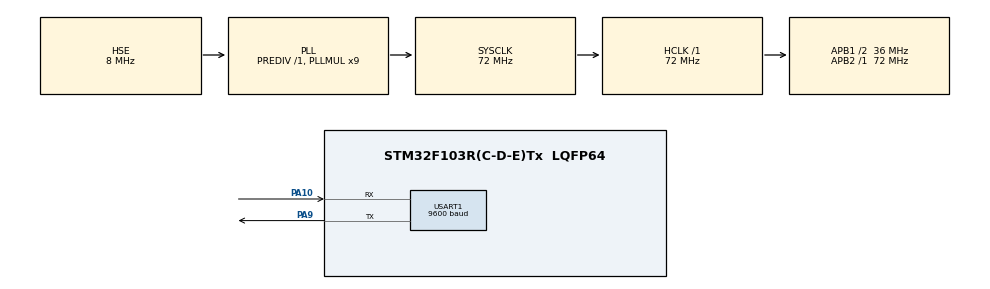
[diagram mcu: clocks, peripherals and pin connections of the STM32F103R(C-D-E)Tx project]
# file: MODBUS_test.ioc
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Mcu.Family=STM32F1
RCC.PLLSourceVirtual=RCC_PLLSOURCE_HSE
PD1-OSC_OUT.Mode=HSE-External-Oscillator
PA10.Mode=Asynchronous
USART1.BaudRate=9600
PD0-OSC_IN.Signal=RCC_OSC_IN
VP_RealThread.RT-Thread_VS_RTOSJjRTAaThread_3.1.3.Mode=RTOSJjRTAaThread
RCC.APB1CLKDivider=RCC_HCLK_DIV2
RCC.SYSCLKSource=RCC_SYSCLKSOURCE_PLLCLK
ProjectManager.StackSize=0x400
PD1-OSC_OUT.Signal=RCC_OSC_OUT
PA13.Signal=SYS_JTMS-SWDIO
PA9.Mode=Asynchronous
ProjectManager.TargetToolchain=Other Toolchains (GPDSC)
RCC.HCLKFreq_Value=72000000
RCC.APB2TimFreq_Value=72000000
PA9.Signal=USART1_TX
RCC.USBFreq_Value=72000000
RCC.AHBFreq_Value=72000000
PD0-OSC_IN.Mode=HSE-External-Oscillator
PB3.Mode=JTAG_4_pins
board=custom
PA15.Mode=JTAG_4_pins
RCC.PLLMUL=RCC_PLL_MUL9
RCC.APB2Freq_Value=72000000
PA14.Mode=JTAG_4_pins
PA13.Mode=JTAG_4_pins
Mcu.Name=STM32F103R(C-D-E)Tx
RealThread.RT-Thread.3.1.3.RTAaThreadCcRTOSJjkernel=true
RCC.LockedElements=AHBOutput
PB3.Signal=SYS_JTDO-TRACESWO
RCC.SYSCLKFreq_VALUE=72000000
Mcu.Package=LQFP64
USART1.VirtualMode=VM_ASYNC
PA10.Signal=USART1_RX
PA14.Signal=SYS_JTCK-SWCLK
PA15.Signal=SYS_JTDI
ProjectManager.HeapSize=0x200
NVIC.PriorityGroup=NVIC_PRIORITYGROUP_4
RCC.APB1TimFreq_Value=72000000
RCC.APB1Freq_Value=36000000

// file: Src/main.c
/* USER CODE BEGIN Header */
/**
  ******************************************************************************
  * @file           : main.c
  * @brief          : Main program body
  ******************************************************************************
  * @attention
  *
  * <h2><center>&copy; Copyright (c) 2020 STMicroelectronics.
  * All rights reserved.</center></h2>
  *
  * This software component is licensed by ST under Ultimate Liberty license
  * SLA0044, the "License"; You may not use this file except in compliance with
  * the License. You may obtain a copy of the License at:
  *                             www.st.com/SLA0044
  *
  ******************************************************************************
  */
/* USER CODE END Header */

#include "main.h"

UART_HandleTypeDef huart1;

void SystemClock_Config(void);
void MX_GPIO_Init(void);
void MX_USART1_UART_Init(void);

/* USER CODE BEGIN 0 */
void rt_hw_console_output(const char *str)
{
    // rt_size_t i = 0, size = 0;
    // char a = '\r';

    // __HAL_UNLOCK(&huart1);

    // size = rt_strlen(str);
    // for (i = 0; i < size; i++)
    // {
    //     if (*(str + i) == '\n')
    //     {
    //         HAL_UART_Transmit(&huart1, (uint8_t *)&a, 1, 50);
    //     }
    //     HAL_UART_Transmit(&huart1, (uint8_t *)(str + i), 1, 50);
    // }
}
   int main(void) {
		 		HAL_Init();
    MX_GPIO_Init();
		MX_USART1_UART_Init();
   HAL_UART_Transmit(&huart1, "123", 3, 3);
   while(1){
     __NOP();
   }
 }
/* USER CODE END 0 */

void SystemClock_Config(void)
{
  RCC_OscInitTypeDef RCC_OscInitStruct = {0};
  RCC_ClkInitTypeDef RCC_ClkInitStruct = {0};

  /** Initializes the CPU, AHB and APB busses clocks
  */
  RCC_OscInitStruct.OscillatorType = RCC_OSCILLATORTYPE_HSE;
  RCC_OscInitStruct.HSEState = RCC_HSE_ON;
  RCC_OscInitStruct.HSEPredivValue = RCC_HSE_PREDIV_DIV1;
  RCC_OscInitStruct.HSIState = RCC_HSI_ON;
  RCC_OscInitStruct.PLL.PLLState = RCC_PLL_ON;
  RCC_OscInitStruct.PLL.PLLSource = RCC_PLLSOURCE_HSE;
  RCC_OscInitStruct.PLL.PLLMUL = RCC_PLL_MUL9;
  if (HAL_RCC_OscConfig(&RCC_OscInitStruct) != HAL_OK)
  {
    Error_Handler();
  }
  /** Initializes the CPU, AHB and APB busses clocks
  */
  RCC_ClkInitStruct.ClockType = RCC_CLOCKTYPE_HCLK|RCC_CLOCKTYPE_SYSCLK
                              |RCC_CLOCKTYPE_PCLK1|RCC_CLOCKTYPE_PCLK2;
  RCC_ClkInitStruct.SYSCLKSource = RCC_SYSCLKSOURCE_PLLCLK;
  RCC_ClkInitStruct.AHBCLKDivider = RCC_SYSCLK_DIV1;
  RCC_ClkInitStruct.APB1CLKDivider = RCC_HCLK_DIV2;
  RCC_ClkInitStruct.APB2CLKDivider = RCC_HCLK_DIV1;

  if (HAL_RCC_ClockConfig(&RCC_ClkInitStruct, FLASH_LATENCY_2) != HAL_OK)
  {
    Error_Handler();
  }
}

void MX_USART1_UART_Init(void)
{

  huart1.Instance = USART1;
  huart1.Init.BaudRate = 9600;
  huart1.Init.WordLength = UART_WORDLENGTH_8B;
  huart1.Init.StopBits = UART_STOPBITS_1;
  huart1.Init.Parity = UART_PARITY_NONE;
  huart1.Init.Mode = UART_MODE_TX_RX;
  huart1.Init.HwFlowCtl = UART_HWCONTROL_NONE;
  huart1.Init.OverSampling = UART_OVERSAMPLING_16;
  if (HAL_UART_Init(&huart1) != HAL_OK)
  {
    Error_Handler();
  }

}

void MX_GPIO_Init(void)
{

  /* GPIO Ports Clock Enable */
  __HAL_RCC_GPIOD_CLK_ENABLE();
  __HAL_RCC_GPIOA_CLK_ENABLE();
  __HAL_RCC_GPIOB_CLK_ENABLE();

}

void Error_Handler(void)
{
}

/************************ (C) COPYRIGHT STMicroelectronics *****END OF FILE****/
